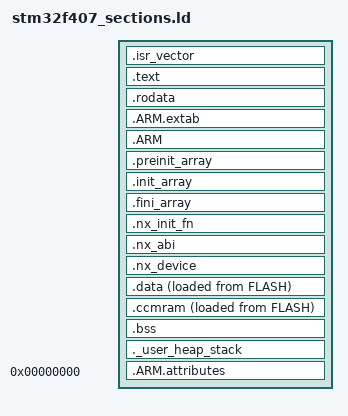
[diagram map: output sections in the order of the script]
/* Sections */
/* Retain compiler ABI evidence even for direct-SDK bring-up applications. */
EXTERN(nx_device_descriptor_bytes)
SECTIONS
{
    /* Vector table must be at the beginning of FLASH */
    .isr_vector :
    {
        . = ALIGN(4);
        KEEP(*(.isr_vector))
        . = ALIGN(4);
    } >FLASH

    /* Program code and constants */
    .text :
    {
        . = ALIGN(4);
        *(.text)
        *(.text*)
        *(.glue_7)
        *(.glue_7t)
        *(.eh_frame)

        KEEP (*(.init))
        KEEP (*(.fini))

        . = ALIGN(4);
        _etext = .;
    } >FLASH

    /* Constant data */
    .rodata :
    {
        . = ALIGN(4);
        *(.rodata)
        *(.rodata*)
        . = ALIGN(4);
    } >FLASH

    .ARM.extab (READONLY) :
    {
        . = ALIGN(4);
        *(.ARM.extab* .gnu.linkonce.armextab.*)
        . = ALIGN(4);
    } >FLASH

    .ARM (READONLY) :
    {
        . = ALIGN(4);
        __exidx_start = .;
        *(.ARM.exidx*)
        __exidx_end = .;
        . = ALIGN(4);
    } >FLASH

    .preinit_array (READONLY) :
    {
        . = ALIGN(4);
        PROVIDE_HIDDEN (__preinit_array_start = .);
        KEEP (*(.preinit_array*))
        PROVIDE_HIDDEN (__preinit_array_end = .);
        . = ALIGN(4);
    } >FLASH

    .init_array (READONLY) :
    {
        . = ALIGN(4);
        PROVIDE_HIDDEN (__init_array_start = .);
        KEEP (*(SORT(.init_array.*)))
        KEEP (*(.init_array*))
        PROVIDE_HIDDEN (__init_array_end = .);
        . = ALIGN(4);
    } >FLASH

    .fini_array (READONLY) :
    {
        . = ALIGN(4);
        PROVIDE_HIDDEN (__fini_array_start = .);
        KEEP (*(SORT(.fini_array.*)))
        KEEP (*(.fini_array*))
        PROVIDE_HIDDEN (__fini_array_end = .);
        . = ALIGN(4);
    } >FLASH

    .nx_init_fn (READONLY) :
    {
        . = ALIGN(4);
        __nx_init_fn_start = .;
        KEEP(*(SORT_BY_NAME(.nx_init_fn.*)))
        __nx_init_fn_end = .;
    } >FLASH

    /* Compiler-derived descriptor ABI used by the artifact checker. */
    .nx_abi (READONLY) :
    {
        . = ALIGN(4);
        KEEP(*(.nx_abi))
    } >FLASH

    /* Nexus HAL device registration section */
    .nx_device (READONLY) :
    {
        . = ALIGN(4);
        __nx_device_start = .;
        KEEP(*(SORT(.nx_device*)))
        __nx_device_end = .;
        . = ALIGN(4);
    } >FLASH

    /* Used by startup to initialize data */
    _sidata = LOADADDR(.data);

    /* Initialized data section */
    .data :
    {
        . = ALIGN(4);
        _sdata = .;
        *(.data)
        *(.data*)
        . = ALIGN(4);
        _edata = .;
    } >RAM AT> FLASH

    /* CCM RAM section (optional) */
    .ccmram :
    {
        . = ALIGN(4);
        _sccmram = .;
        *(.ccmram)
        *(.ccmram*)
        . = ALIGN(4);
        _eccmram = .;
    } >CCMRAM AT> FLASH

    /* Uninitialized data section */
    .bss :
    {
        . = ALIGN(4);
        _sbss = .;
        __bss_start__ = _sbss;
        *(.bss)
        *(.bss*)
        *(COMMON)
        . = ALIGN(4);
        _ebss = .;
        __bss_end__ = _ebss;
    } >RAM

    /* User heap and stack */
    ._user_heap_stack :
    {
        . = ALIGN(8);
        PROVIDE ( end = . );
        PROVIDE ( _end = . );
        . = . + _Min_Heap_Size;
        . = . + _Min_Stack_Size;
        . = ALIGN(8);
    } >RAM

    .ARM.attributes 0 : { *(.ARM.attributes) }
}
